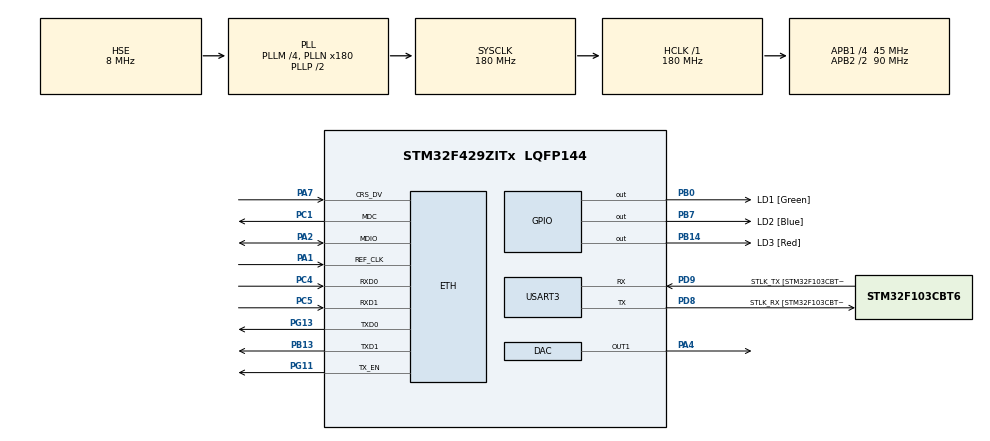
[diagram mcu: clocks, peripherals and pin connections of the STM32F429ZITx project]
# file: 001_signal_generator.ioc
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DAC.DAC_Trigger=DAC_TRIGGER_T6_TRGO
Dma.DAC1.0.Direction=DMA_MEMORY_TO_PERIPH
Dma.DAC1.0.FIFOMode=DMA_FIFOMODE_DISABLE
Dma.DAC1.0.Instance=DMA1_Stream5
Dma.DAC1.0.MemDataAlignment=DMA_MDATAALIGN_HALFWORD
Dma.DAC1.0.MemInc=DMA_MINC_ENABLE
Dma.DAC1.0.Mode=DMA_CIRCULAR
Dma.DAC1.0.PeriphDataAlignment=DMA_PDATAALIGN_HALFWORD
Dma.DAC1.0.PeriphInc=DMA_PINC_DISABLE
Dma.DAC1.0.Priority=DMA_PRIORITY_HIGH
Dma.Request0=DAC1
ETH.MediaInterface=HAL_ETH_RMII_MODE
ETH.RxMode=ETH_RXINTERRUPT_MODE
FREERTOS.Tasks01=UdpTask,24,512,vUdpTask,Default,NULL,Static,UdpTaskBuffer,UdpTaskControlBlock
FREERTOS.configENABLE_FPU=1
FREERTOS.configUSE_NEWLIB_REENTRANT=1
LWIP.BSP.number=1
LWIP.IP_ADDRESS=192.168.172.098
LWIP.LWIP_DHCP=0
LWIP.LWIP_PERF=0
LWIP.LWIP_TCP=0
LWIP.MEMP_NUM_TCP_PCB=0
LWIP.MEM_SIZE=1600*12
LWIP.NETMASK_ADDRESS=255.255.255.000
LWIP.Version=v2.1.2_Cube
LWIP0.BSP.STBoard=false
LWIP0.BSP.api=BSP_COMPONENT_DRIVER
LWIP0.BSP.component=LAN8742
LWIP0.BSP.instance=LAN8742
LWIP0.BSP.name=Driver_PHY
LWIP0.BSP.semaphore=S_LAN8742
LWIP0.BSP.solution=LAN8742
Mcu.Family=STM32F4
Mcu.Name=STM32F429ZITx
Mcu.Package=LQFP144
NVIC.ETH_IRQn=true\:5\:0\:false\:false\:true\:true\:true\:true\:true
NVIC.PriorityGroup=NVIC_PRIORITYGROUP_4
NVIC.TIM6_DAC_IRQn=true\:5\:0\:false\:false\:true\:false\:true\:true\:true
NVIC.TIM8_TRG_COM_TIM14_IRQn=true\:15\:0\:false\:false\:true\:false\:false\:true\:true
NVIC.TimeBase=TIM8_TRG_COM_TIM14_IRQn
NVIC.TimeBaseIP=TIM14
PA1.Mode=RMII
PA1.Signal=ETH_REF_CLK
PA2.Mode=RMII
PA2.Signal=ETH_MDIO
PA4.Signal=COMP_DAC1_group
PA7.Mode=RMII
PA7.Signal=ETH_CRS_DV
PB0.GPIO_Label=LD1 [Green]
PB0.Signal=GPIO_Output
PB13.Mode=RMII
PB13.Signal=ETH_TXD1
PB14.GPIO_Label=LD3 [Red]
PB14.Signal=GPIO_Output
PB7.GPIO_Label=LD2 [Blue]
PB7.Signal=GPIO_Output
PC1.Mode=RMII
PC1.Signal=ETH_MDC
PC4.Mode=RMII
PC4.Signal=ETH_RXD0
PC5.Mode=RMII
PC5.Signal=ETH_RXD1
PD8.GPIO_Label=STLK_RX [STM32F103CBT6_PA3]
PD8.Mode=Asynchronous
PD8.Signal=USART3_TX
PD9.GPIO_Label=STLK_TX [STM32F103CBT6_PA2]
PD9.Mode=Asynchronous
PD9.Signal=USART3_RX
PG11.Mode=RMII
PG11.Signal=ETH_TX_EN
PG13.Mode=RMII
PG13.Signal=ETH_TXD0
PH0/OSC_IN.GPIO_Label=OSC_IN
PH0/OSC_IN.Mode=HSE-External-Oscillator
PH0/OSC_IN.Signal=RCC_OSC_IN
PH1/OSC_OUT.GPIO_Label=OSC_OUT
PH1/OSC_OUT.Mode=HSE-External-Oscillator
PH1/OSC_OUT.Signal=RCC_OSC_OUT
ProjectManager.HeapSize=0x200
ProjectManager.StackSize=0x400
ProjectManager.TargetToolchain=STM32CubeIDE
RCC.48MHZClocksFreq_Value=51428571.428571425
RCC.AHBFreq_Value=180000000
RCC.APB1CLKDivider=RCC_HCLK_DIV4
RCC.APB1Freq_Value=45000000
RCC.APB1TimFreq_Value=90000000
RCC.APB2CLKDivider=RCC_HCLK_DIV2
RCC.APB2Freq_Value=90000000
RCC.APB2TimFreq_Value=180000000
RCC.CortexFreq_Value=180000000
RCC.EnbaleCSS=true
RCC.HCLKFreq_Value=180000000
RCC.HSE_VALUE=8000000
RCC.HSI_VALUE=16000000
RCC.LSE_VALUE=32768
RCC.PLLM=4
RCC.PLLMUL=RCC_PLL_MUL9
RCC.PLLN=180
RCC.PLLQ=7
RCC.PLLSourceVirtual=RCC_PLLSOURCE_HSE
RCC.PRESCALERUSB=RCC_USBCLKSOURCE_PLL_DIV1_5
RCC.SYSCLKFreq_VALUE=180000000
RCC.SYSCLKSource=RCC_SYSCLKSOURCE_PLLCLK
RCC.SYSCLKSourceVirtual=RCC_SYSCLKSOURCE_PLLCLK
RCC.USBFreq_Value=48000000
RCC.VCOOutputFreq_Value=360000000
SH.COMP_DAC1_group.0=DAC_OUT1,DAC_OUT1
TIM6.AutoReloadPreload=TIM_AUTORELOAD_PRELOAD_ENABLE
TIM6.Period=4499
TIM6.Prescaler=0
TIM6.TIM_MasterOutputTrigger=TIM_TRGO_UPDATE
USART3.VirtualMode=VM_ASYNC
VP_FREERTOS_VS_CMSIS_V2.Mode=CMSIS_V2
VP_LWIP_VS_Enabled.Mode=Enabled
VP_SYS_VS_tim14.Mode=TIM14
VP_TIM6_VS_ClockSourceINT.Mode=Enable_Timer
board=NUCLEO-F429ZI

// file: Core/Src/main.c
/* USER CODE BEGIN Header */
/**
  ******************************************************************************
  * @file           : main.c
  * @brief          : Main program body
  ******************************************************************************
  * @attention
  *
  * Copyright (c) 2026 STMicroelectronics.
  * All rights reserved.
  *
  * This software is licensed under terms that can be found in the LICENSE file
  * in the root directory of this software component.
  * If no LICENSE file comes with this software, it is provided AS-IS.
  *
  ******************************************************************************
  */
/* USER CODE END Header */
#include "main.h"
#include "cmsis_os.h"
#include "dac.h"
#include "dma.h"
#include "lwip.h"
#include "tim.h"
#include "usart.h"
#include "gpio.h"

/* USER CODE BEGIN Includes */
#include "wave.h"
/* USER CODE END Includes */

void SystemClock_Config(void);
void MX_FREERTOS_Init(void);

int main(void)
{

  /* MCU Configuration--------------------------------------------------------*/

  /* Reset of all peripherals, Initializes the Flash interface and the Systick. */
  HAL_Init();

  /* Configure the system clock */
  SystemClock_Config();

  /* Initialize all configured peripherals */
  MX_GPIO_Init();
  MX_DMA_Init();
  MX_USART3_UART_Init();
  MX_DAC_Init();
  MX_TIM6_Init();
  /* USER CODE BEGIN 2 */
  wave_start(&hdac, &htim6);
  /* USER CODE END 2 */

  /* Init scheduler */
  osKernelInitialize();  /* Call init function for freertos objects (in cmsis_os2.c) */
  MX_FREERTOS_Init();

  /* Start scheduler */
  osKernelStart();

  /* We should never get here as control is now taken by the scheduler */

  /* Infinite loop */
  while (1)
  {

  }
}

void SystemClock_Config(void)
{
  RCC_OscInitTypeDef RCC_OscInitStruct = {0};
  RCC_ClkInitTypeDef RCC_ClkInitStruct = {0};

  /** Configure the main internal regulator output voltage
  */
  __HAL_RCC_PWR_CLK_ENABLE();
  __HAL_PWR_VOLTAGESCALING_CONFIG(PWR_REGULATOR_VOLTAGE_SCALE1);

  /** Initializes the RCC Oscillators according to the specified parameters
  * in the RCC_OscInitTypeDef structure.
  */
  RCC_OscInitStruct.OscillatorType = RCC_OSCILLATORTYPE_HSE;
  RCC_OscInitStruct.HSEState = RCC_HSE_ON;
  RCC_OscInitStruct.PLL.PLLState = RCC_PLL_ON;
  RCC_OscInitStruct.PLL.PLLSource = RCC_PLLSOURCE_HSE;
  RCC_OscInitStruct.PLL.PLLM = 4;
  RCC_OscInitStruct.PLL.PLLN = 180;
  RCC_OscInitStruct.PLL.PLLP = RCC_PLLP_DIV2;
  RCC_OscInitStruct.PLL.PLLQ = 7;
  if (HAL_RCC_OscConfig(&RCC_OscInitStruct) != HAL_OK)
  {
    Error_Handler();
  }

  /** Activate the Over-Drive mode
  */
  if (HAL_PWREx_EnableOverDrive() != HAL_OK)
  {
    Error_Handler();
  }

  /** Initializes the CPU, AHB and APB buses clocks
  */
  RCC_ClkInitStruct.ClockType = RCC_CLOCKTYPE_HCLK|RCC_CLOCKTYPE_SYSCLK
                              |RCC_CLOCKTYPE_PCLK1|RCC_CLOCKTYPE_PCLK2;
  RCC_ClkInitStruct.SYSCLKSource = RCC_SYSCLKSOURCE_PLLCLK;
  RCC_ClkInitStruct.AHBCLKDivider = RCC_SYSCLK_DIV1;
  RCC_ClkInitStruct.APB1CLKDivider = RCC_HCLK_DIV4;
  RCC_ClkInitStruct.APB2CLKDivider = RCC_HCLK_DIV2;

  if (HAL_RCC_ClockConfig(&RCC_ClkInitStruct, FLASH_LATENCY_5) != HAL_OK)
  {
    Error_Handler();
  }

  /** Enables the Clock Security System
  */
  HAL_RCC_EnableCSS();
}

void HAL_TIM_PeriodElapsedCallback(TIM_HandleTypeDef *htim)
{
  if (htim->Instance == TIM14)
  {
    HAL_IncTick();
  }
}

void Error_Handler(void)
{
  __disable_irq();
  while (1)
  {
  }
}

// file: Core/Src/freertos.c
/* USER CODE BEGIN Header */
/**
  ******************************************************************************
  * File Name          : freertos.c
  * Description        : Code for freertos applications
  ******************************************************************************
  * @attention
  *
  * Copyright (c) 2026 STMicroelectronics.
  * All rights reserved.
  *
  * This software is licensed under terms that can be found in the LICENSE file
  * in the root directory of this software component.
  * If no LICENSE file comes with this software, it is provided AS-IS.
  *
  ******************************************************************************
  */
/* USER CODE END Header */

#include "FreeRTOS.h"
#include "task.h"
#include "main.h"
#include "cmsis_os.h"

/* USER CODE BEGIN Includes */
#include "signal_remote.h"
/* USER CODE END Includes */

typedef StaticTask_t osStaticThreadDef_t;

/* Definitions for UdpTask */
osThreadId_t UdpTaskHandle;
uint32_t UdpTaskBuffer[ 512 ];
osStaticThreadDef_t UdpTaskControlBlock;
const osThreadAttr_t UdpTask_attributes = {
  .name = "UdpTask",
  .cb_mem = &UdpTaskControlBlock,
  .cb_size = sizeof(UdpTaskControlBlock),
  .stack_mem = &UdpTaskBuffer[0],
  .stack_size = sizeof(UdpTaskBuffer),
  .priority = (osPriority_t) osPriorityNormal,
};

void vUdpTask(void *argument);

extern void MX_LWIP_Init(void);
void MX_FREERTOS_Init(void); /* (MISRA C 2004 rule 8.1) */

void MX_FREERTOS_Init(void) {

  /* Create the thread(s) */
  /* creation of UdpTask */
  UdpTaskHandle = osThreadNew(vUdpTask, NULL, &UdpTask_attributes);

}

void vUdpTask(void *argument)
{
  /* init code for LWIP */
  MX_LWIP_Init();
  /* USER CODE BEGIN vUdpTask */
  /* Studyodan gelen sinyal tablolarini (SPTG, UDP 50506) dinler ve DAC1'den calar; geri donmez. */
  signal_remote_run();
  /* Infinite loop */
  for(;;)
  {
    osDelay(1);
  }
  /* USER CODE END vUdpTask */
}
